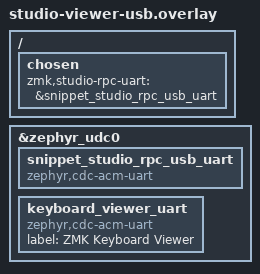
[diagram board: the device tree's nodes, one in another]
/ {
    chosen {
        zmk,studio-rpc-uart = &snippet_studio_rpc_usb_uart;
    };
};

&zephyr_udc0 {
    snippet_studio_rpc_usb_uart: snippet_studio_rpc_usb_uart {
        compatible = "zephyr,cdc-acm-uart";
    };
    keyboard_viewer_uart: keyboard_viewer_uart {
        compatible = "zephyr,cdc-acm-uart";
        label = "ZMK Keyboard Viewer";
    };
};
